# GD32L235x register map
File version: 1.0
CPU: CM23 r1p0, little endian, no MPU, no FPU, 2 interrupt priority bits
Registers are 32-bit, read-write, reset 0x0 unless marked. A register's access mark holds for its fields unless they carry their own. Offsets are from the block's base; [hi:lo] are bit positions; {n}, {i} and the like mark numbered series.

## TIMER5 — Basic-timers
Base 0x40001000
Same registers: TIMER6 0x40001400
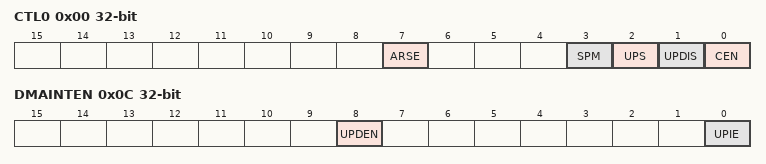
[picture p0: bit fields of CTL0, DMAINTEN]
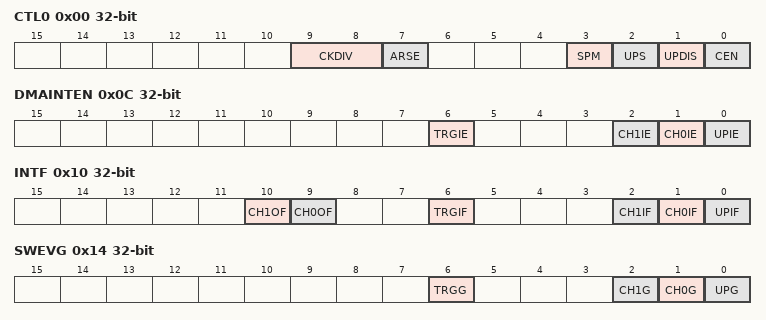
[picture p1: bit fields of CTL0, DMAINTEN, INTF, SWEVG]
0x00 CTL0 — control register 0
  [7] ARSE — Auto-reload preload enable
  [3] SPM — One-pulse mode
  [2] UPS — Update request source
  [1] UPDIS — Update disable
  [0] CEN — Counter enable
0x04 CTL1 — control register 1
  [6:4] MMC — Master mode selection
0x0C DMAINTEN — DMA/Interrupt enable register
  [8] UPDEN — Update DMA request enable
  [0] UPIE — Update interrupt enable
0x10 INTF — status register
  [0] UPIF — Update interrupt flag
0x14 SWEVG wo — event generation register
  [0] UPG — Update generation
0x24 CNT — counter
  [15:0] CNT — Low counter value
0x28 PSC — prescaler
  [15:0] PSC — Prescaler value
0x2C CAR — auto-reload register
  [15:0] CARL — Low Auto-reload value

## TIMER8 — General-purpose-timers
Base 0x40014C00
Same registers: TIMER11 0x40001800
0x00 CTL0 — control register 0
  [9:8] CKDIV — Clock division
  [7] ARSE — Auto-reload shadow enable
  [3] SPM — Single pulse mode
  [2] UPS — Update source
  [1] UPDIS — Update disable
  [0] CEN — Counter enable
0x08 SMCFG 16-bit — slave mode configuration register
  [7] MSM — Master-slave mode
0x0C DMAINTEN — DMA and interrupt enable register
  [6] TRGIE — Trigger interrupt enable
  [2] CH1IE — Channel 1 capture/compare interrupt enable
  [1] CH0IE — Channel 0 capture/compare interrupt enable
  [0] UPIE — Update interrupt enable
0x10 INTF — interrupt flag register
  [10] CH1OF — Channel 1 over capture flag
  [9] CH0OF — Channel 0 over capture flag
  [6] TRGIF — Trigger interrupt flag
  [2] CH1IF — Channel 1 capture/compare interrupt flag
  [1] CH0IF — Channel 0 capture/compare interrupt flag
  [0] UPIF — Update interrupt flag
0x14 SWEVG wo — event generation register
  [6] TRGG — Trigger event generation
  [2] CH1G — Channel 1 capture or compare event generation
  [1] CH0G — Channel 0 capture or compare event generation
  [0] UPG — Update generation
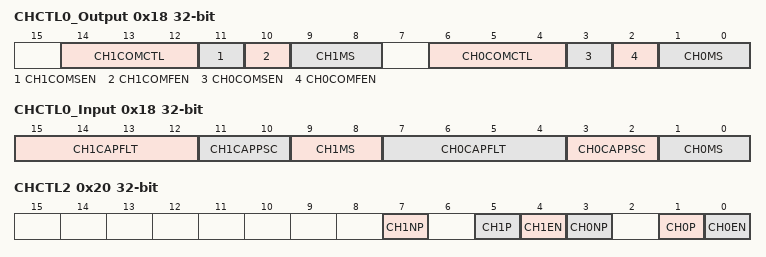
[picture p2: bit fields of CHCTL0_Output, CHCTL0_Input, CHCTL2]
0x18 CHCTL0_Output — Channel control register 0 (output mode)
  [14:12] CH1COMCTL — Channel 1 compare output control
  [11] CH1COMSEN — Channel 1 output compare shadow enable
  [10] CH1COMFEN — Channel 1 output compare fast enable
  [9:8] CH1MS — Channel 1 mode selection
  [6:4] CH0COMCTL — Channel 0 compare output control
  [3] CH0COMSEN — Channel 0 compare output shadow enable
  [2] CH0COMFEN — Channel 0 output compare fast enable
  [1:0] CH0MS — Channel 0 I/O mode selection
0x18 CHCTL0_Input (alternate view of CHCTL0_Output) — Channel control register 0 (input mode)
  [15:12] CH1CAPFLT — Channel 1 input capture filter control
  [11:10] CH1CAPPSC — Channel 1 input capture prescaler
  [9:8] CH1MS — Channel 1 mode selection
  [7:4] CH0CAPFLT — Channel 0 input capture filter control
  [3:2] CH0CAPPSC — Channel 0 input capture prescaler
  [1:0] CH0MS — Channel 0 mode selection
0x20 CHCTL2 — Channel control register 2
  [7] CH1NP — Channel 1 complementary output polarity
  [5] CH1P — Channel 1 capture/compare function polarity
  [4] CH1EN — Channel 1 capture/compare function enable
  [3] CH0NP — Channel 0 complementary output polarity
  [1] CH0P — Channel 0 capture/compare function polarity
  [0] CH0EN — Channel 0 capture/compare function enable
0x24 CNT — Counter register
  [15:0] CNT — current counter value
0x28 PSC — Prescaler register
  [15:0] PSC — Prescaler value of the counter clock
0x2C CAR — Counter auto reload register
  [15:0] CARL — Counter auto reload value
0x34 CH0CV — Channel 0 capture/compare value register
  [15:0] CH0VAL — Capture or compare value of channel0
0x38 CH1CV 16-bit — Channel 1 capture/compare value register
  [15:0] CH1VAL — Capture or compare value of channel1
0x50 IRMP — Channel input remap register
  [1:0] CI0_RMP — Channel 0 input remap
0xFC CFG — configuration register
  [1] CHVSEL — Write CHxVAL register selection

## TRNG — Ture random number generator
Base 0x50060800
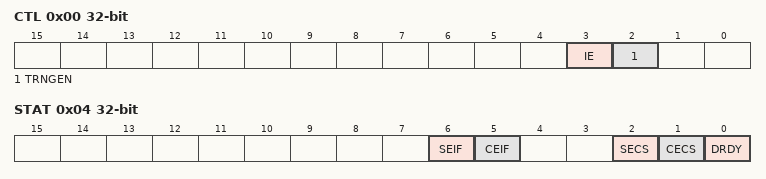
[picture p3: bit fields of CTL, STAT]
0x00 CTL — Control register
  [3] IE — Interrupt bit
  [2] TRNGEN — TRNG enable bit
0x04 STAT access per field — Status register
  [6] SEIF rw — Seed error interrupt flag
  [5] CEIF rw — Clock error interrupt flag
  [2] SECS ro — Seed error current status
  [1] CECS ro — Clock error current status
  [0] DRDY ro — Random data ready status bit
0x08 DATA ro
  [31:0] TRNDATA — 32-bit random data

## USBD — Universal serial bus full-speed device interface
Base 0x40005C00
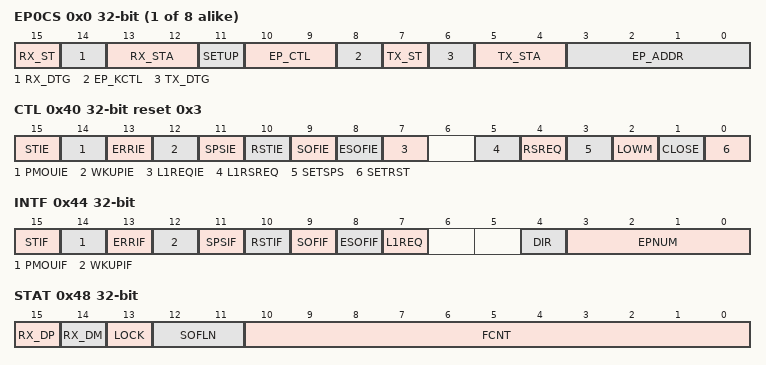
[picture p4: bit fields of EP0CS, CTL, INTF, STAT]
{0x0+4i} EP{i}CS access per field (i=0..7) — endpoint {i} register
  [15] RX_ST rw — Reception Successful Transferred
  [14] RX_DTG rw — Reception Data PID Toggle
  [13:12] RX_STA rw — Reception status bits
  [11] SETUP ro — Setup transaction completed
  [10:9] EP_CTL rw — Endpoint type control
  [8] EP_KCTL rw — Endpoint kind control
  [7] TX_ST rw — Transmission Successful Transfer
  [6] TX_DTG rw — Transmission Data PID Toggle
  [5:4] TX_STA rw — Status bits, for transmission transfers
  [3:0] EP_ADDR rw — Endpoint address
0x40 CTL reset 0x3 — control register
  [15] STIE — Successful transfer interrupt enable
  [14] PMOUIE — Packet memory overrun / underrun interrupt enable
  [13] ERRIE — Error interrupt mask
  [12] WKUPIE — Wakeup interrupt mask
  [11] SPSIE — Suspend state interrupt enable
  [10] RSTIE — USB reset interrupt enable
  [9] SOFIE — Start of frame interrupt enable
  [8] ESOFIE — Expected start of frame interrupt enable
  [7] L1REQIE — LPM L1 state request interrupt enable
  [5] L1RSREQ — LPM L1 resume request
  [4] RSREQ — Send resume request
  [3] SETSPS — Set suspend state
  [2] LOWM — Low-power mode
  [1] CLOSE — USB close
  [0] SETRST — USB Reset
0x44 INTF access per field — interrupt flag register
  [15] STIF ro — Successful transfer interrupt flag
  [14] PMOUIF rw — Packet memory overrun / underrun interrupt flag
  [13] ERRIF rw — Error interrupt flag
  [12] WKUPIF rw — Wakeup interrupt flag
  [11] SPSIF rw — Suspend state interrupt flag
  [10] RSTIF rw — USB reset interrupt flag
  [9] SOFIF rw — Start of frame interrupt flag
  [8] ESOFIF rw — Expected start of frame interrupt flag
  [7] L1REQ rw — LPM L1 transaction is successfully received and acknowledged
  [4] DIR ro — Direction of transaction
  [3:0] EPNUM ro — Endpoint Number
0x48 STAT ro — Status register
  [15] RX_DP — Receive data + line status
  [14] RX_DM — Receive data - line status
  [13] LOCK — Locked the USB
  [12:11] SOFLN — SOF lost number
  [10:0] FCNT — Frame number counter
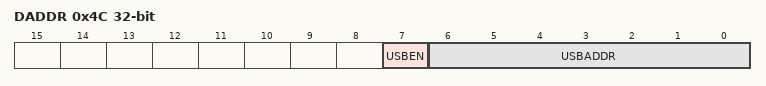
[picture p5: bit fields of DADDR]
0x4C DADDR — device address register
  [7] USBEN — USB device enable
  [6:0] USBADDR — USB device address
0x50 BADDR — Buffer address register
  [15:3] BAR — Buffer address

## VREF
Base 0x40010030
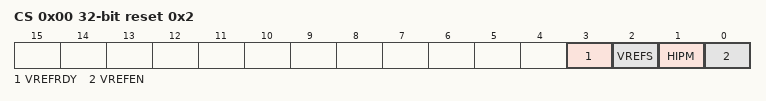
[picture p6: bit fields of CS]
0x00 CS access per field reset 0x2 — Control and status register
  [3] VREFRDY ro — VREF ready
  [2] VREFS rw — Voltage reference scale
  [1] HIPM rw — High impedance mode
  [0] VREFEN rw — VREF enable
0x04 CALIB — Calibration register
  [5:0] VREFCAL — VREF calibration

## WWDGT — Window watchdog timer
Base 0x40002C00
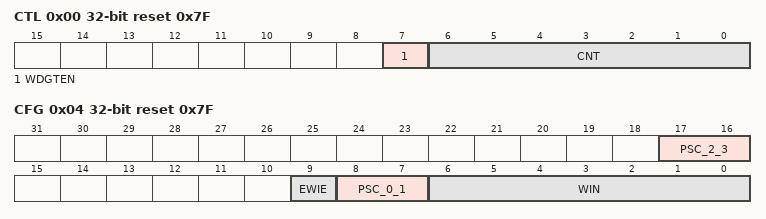
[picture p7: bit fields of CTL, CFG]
0x00 CTL reset 0x7F — Control register
  [7] WDGTEN — Activation bit
  [6:0] CNT — 7-bit counter
0x04 CFG reset 0x7F — Configuration register
  [17:16] PSC_2_3 — Prescaler
  [9] EWIE — Early wakeup interrupt
  [8:7] PSC_0_1 — Prescaler
  [6:0] WIN — 7-bit window value
0x08 STAT — Status register
  [0] EWIF — Early wakeup interrupt flag
